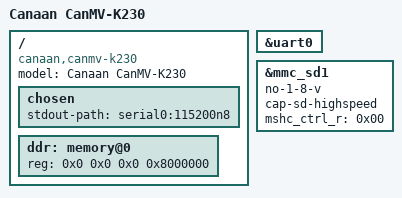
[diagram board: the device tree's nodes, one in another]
// SPDX-License-Identifier: GPL-2.0 OR MIT
/*
 * Copyright (C) 2024 Yangyu Chen <cyy@cyyself.name>
 */

#include "k230.dtsi"

/ {
	model = "Canaan CanMV-K230";
	compatible = "canaan,canmv-k230", "canaan,kendryte-k230";

	chosen {
		stdout-path = "serial0:115200n8";
	};

	ddr: memory@0 {
		device_type = "memory";
		reg = <0x0 0x0 0x0 0x8000000>;
	};

};

&uart0 {
	status = "okay";
};

&mmc_sd1{
    status = "okay";
    no-1-8-v;
    cap-sd-highspeed;
    mshc_ctrl_r = <0x00>;
};
